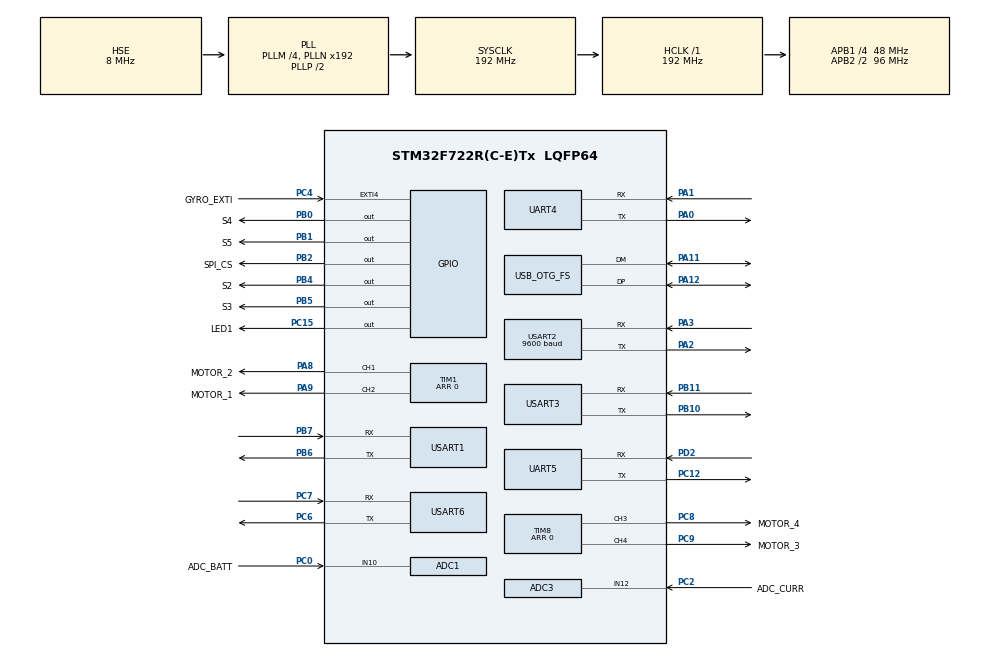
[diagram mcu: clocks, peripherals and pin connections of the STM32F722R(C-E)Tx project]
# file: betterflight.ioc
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ADC1.Channel-0\#ChannelRegularConversion=ADC_CHANNEL_10
ADC1.ClockPrescaler=ADC_CLOCK_SYNC_PCLK_DIV4
ADC1.NbrOfConversionFlag=1
ADC1.Rank-0\#ChannelRegularConversion=1
ADC1.SamplingTime-0\#ChannelRegularConversion=ADC_SAMPLETIME_3CYCLES
ADC1.master=1
ADC3.Channel-0\#ChannelRegularConversion=ADC_CHANNEL_12
ADC3.ClockPrescaler=ADC_CLOCK_SYNC_PCLK_DIV4
ADC3.NbrOfConversionFlag=1
ADC3.Rank-0\#ChannelRegularConversion=1
ADC3.SamplingTime-0\#ChannelRegularConversion=ADC_SAMPLETIME_3CYCLES
Dma.Request0=TIM1_CH1
Dma.Request1=TIM8_CH3
Dma.Request2=TIM8_CH4/TRIG/COM
Dma.Request3=TIM1_CH2
Dma.TIM1_CH1.0.Direction=DMA_MEMORY_TO_PERIPH
Dma.TIM1_CH1.0.FIFOMode=DMA_FIFOMODE_ENABLE
Dma.TIM1_CH1.0.FIFOThreshold=DMA_FIFO_THRESHOLD_1QUARTERFULL
Dma.TIM1_CH1.0.Instance=DMA2_Stream1
Dma.TIM1_CH1.0.MemBurst=DMA_MBURST_SINGLE
Dma.TIM1_CH1.0.MemDataAlignment=DMA_MDATAALIGN_WORD
Dma.TIM1_CH1.0.MemInc=DMA_MINC_ENABLE
Dma.TIM1_CH1.0.Mode=DMA_NORMAL
Dma.TIM1_CH1.0.PeriphBurst=DMA_PBURST_SINGLE
Dma.TIM1_CH1.0.PeriphDataAlignment=DMA_PDATAALIGN_WORD
Dma.TIM1_CH1.0.PeriphInc=DMA_PINC_DISABLE
Dma.TIM1_CH1.0.Priority=DMA_PRIORITY_HIGH
Dma.TIM1_CH2.3.Direction=DMA_MEMORY_TO_PERIPH
Dma.TIM1_CH2.3.FIFOMode=DMA_FIFOMODE_ENABLE
Dma.TIM1_CH2.3.FIFOThreshold=DMA_FIFO_THRESHOLD_FULL
Dma.TIM1_CH2.3.Instance=DMA2_Stream2
Dma.TIM1_CH2.3.MemBurst=DMA_MBURST_SINGLE
Dma.TIM1_CH2.3.MemDataAlignment=DMA_MDATAALIGN_WORD
Dma.TIM1_CH2.3.MemInc=DMA_MINC_ENABLE
Dma.TIM1_CH2.3.Mode=DMA_NORMAL
Dma.TIM1_CH2.3.PeriphBurst=DMA_PBURST_SINGLE
Dma.TIM1_CH2.3.PeriphDataAlignment=DMA_PDATAALIGN_WORD
Dma.TIM1_CH2.3.PeriphInc=DMA_PINC_DISABLE
Dma.TIM1_CH2.3.Priority=DMA_PRIORITY_HIGH
Dma.TIM8_CH3.1.Direction=DMA_MEMORY_TO_PERIPH
Dma.TIM8_CH3.1.FIFOMode=DMA_FIFOMODE_ENABLE
Dma.TIM8_CH3.1.FIFOThreshold=DMA_FIFO_THRESHOLD_1QUARTERFULL
Dma.TIM8_CH3.1.Instance=DMA2_Stream4
Dma.TIM8_CH3.1.MemBurst=DMA_MBURST_SINGLE
Dma.TIM8_CH3.1.MemDataAlignment=DMA_MDATAALIGN_WORD
Dma.TIM8_CH3.1.MemInc=DMA_MINC_ENABLE
Dma.TIM8_CH3.1.Mode=DMA_NORMAL
Dma.TIM8_CH3.1.PeriphBurst=DMA_PBURST_SINGLE
Dma.TIM8_CH3.1.PeriphDataAlignment=DMA_PDATAALIGN_WORD
Dma.TIM8_CH3.1.PeriphInc=DMA_PINC_DISABLE
Dma.TIM8_CH3.1.Priority=DMA_PRIORITY_HIGH
Dma.TIM8_CH4/TRIG/COM.2.Direction=DMA_MEMORY_TO_PERIPH
Dma.TIM8_CH4/TRIG/COM.2.FIFOMode=DMA_FIFOMODE_ENABLE
Dma.TIM8_CH4/TRIG/COM.2.FIFOThreshold=DMA_FIFO_THRESHOLD_1QUARTERFULL
Dma.TIM8_CH4/TRIG/COM.2.Instance=DMA2_Stream7
Dma.TIM8_CH4/TRIG/COM.2.MemBurst=DMA_MBURST_SINGLE
Dma.TIM8_CH4/TRIG/COM.2.MemDataAlignment=DMA_MDATAALIGN_WORD
Dma.TIM8_CH4/TRIG/COM.2.MemInc=DMA_MINC_ENABLE
Dma.TIM8_CH4/TRIG/COM.2.Mode=DMA_NORMAL
Dma.TIM8_CH4/TRIG/COM.2.PeriphBurst=DMA_PBURST_SINGLE
Dma.TIM8_CH4/TRIG/COM.2.PeriphDataAlignment=DMA_PDATAALIGN_WORD
Dma.TIM8_CH4/TRIG/COM.2.PeriphInc=DMA_PINC_DISABLE
Dma.TIM8_CH4/TRIG/COM.2.Priority=DMA_PRIORITY_HIGH
Mcu.Family=STM32F7
Mcu.Name=STM32F722R(C-E)Tx
Mcu.Package=LQFP64
NVIC.DMA2_Stream1_IRQn=true\:0\:0\:false\:false\:true\:false\:true\:true
NVIC.DMA2_Stream2_IRQn=true\:0\:0\:false\:false\:true\:false\:true\:true
NVIC.DMA2_Stream4_IRQn=true\:0\:0\:false\:false\:true\:false\:true\:true
NVIC.DMA2_Stream7_IRQn=true\:0\:0\:false\:false\:true\:false\:true\:true
NVIC.EXTI4_IRQn=true\:0\:0\:false\:false\:true\:true\:true\:true
NVIC.OTG_FS_IRQn=true\:0\:0\:false\:false\:true\:false\:true\:true
NVIC.PriorityGroup=NVIC_PRIORITYGROUP_4
NVIC.USART2_IRQn=true\:0\:0\:false\:false\:true\:true\:true\:true
PA0-WKUP.Mode=Asynchronous
PA0-WKUP.Signal=UART4_TX
PA1.Mode=Asynchronous
PA1.Signal=UART4_RX
PA11.Mode=Device_Only
PA11.Signal=USB_OTG_FS_DM
PA12.Mode=Device_Only
PA12.Signal=USB_OTG_FS_DP
PA13.Mode=Serial_Wire
PA13.Signal=SYS_JTMS-SWDIO
PA14.Mode=Serial_Wire
PA14.Signal=SYS_JTCK-SWCLK
PA15.GPIO_Label=LED_STRIP
PA15.Signal=S_TIM2_CH1_ETR
PA2.Mode=Asynchronous
PA2.Signal=USART2_TX
PA3.Mode=Asynchronous
PA3.Signal=USART2_RX
PA5.GPIO_Label=SPI_SCK
PA5.Signal=SPI1_SCK
PA6.GPIO_Label=SPI_MISO
PA6.Signal=SPI1_MISO
PA7.GPIO_Label=SPI_MOSI
PA7.Signal=SPI1_MOSI
PA8.GPIO_Label=MOTOR_2
PA8.Signal=S_TIM1_CH1
PA9.GPIO_Label=MOTOR_1
PA9.Signal=S_TIM1_CH2
PB0.GPIO_Label=S4
PB0.GPIO_PuPd=GPIO_PULLUP
PB0.GPIO_Speed=GPIO_SPEED_FREQ_VERY_HIGH
PB0.PinState=GPIO_PIN_SET
PB0.Signal=GPIO_Output
PB1.GPIO_Label=S5
PB1.GPIO_PuPd=GPIO_PULLUP
PB1.GPIO_Speed=GPIO_SPEED_FREQ_VERY_HIGH
PB1.PinState=GPIO_PIN_SET
PB1.Signal=GPIO_Output
PB10.Mode=Asynchronous
PB10.Signal=USART3_TX
PB11.Mode=Asynchronous
PB11.Signal=USART3_RX
PB14.GPIO_Label=S1
PB14.Signal=S_TIM12_CH1
PB2.GPIO_Label=SPI_CS
PB2.PinState=GPIO_PIN_SET
PB2.Signal=GPIO_Output
PB4.GPIO_Label=S2
PB4.GPIO_PuPd=GPIO_PULLUP
PB4.GPIO_Speed=GPIO_SPEED_FREQ_VERY_HIGH
PB4.PinState=GPIO_PIN_SET
PB4.Signal=GPIO_Output
PB5.GPIO_Label=S3
PB5.GPIO_PuPd=GPIO_PULLUP
PB5.GPIO_Speed=GPIO_SPEED_FREQ_VERY_HIGH
PB5.PinState=GPIO_PIN_SET
PB5.Signal=GPIO_Output
PB6.Mode=Asynchronous
PB6.Signal=USART1_TX
PB7.Mode=Asynchronous
PB7.Signal=USART1_RX
PB8.Signal=I2C1_SCL
PB9.Signal=I2C1_SDA
PC0.GPIO_Label=ADC_BATT
PC0.Signal=ADCx_IN10
PC12.Mode=Asynchronous
PC12.Signal=UART5_TX
PC15-OSC32_OUT.GPIO_Label=LED1
PC15-OSC32_OUT.Signal=GPIO_Output
PC2.GPIO_Label=ADC_CURR
PC2.Signal=ADCx_IN12
PC4.GPIO_Label=GYRO_EXTI
PC4.Signal=GPXTI4
PC6.Mode=Asynchronous
PC6.Signal=USART6_TX
PC7.Mode=Asynchronous
PC7.Signal=USART6_RX
PC8.GPIO_Label=MOTOR_4
PC8.Signal=S_TIM8_CH3
PC9.GPIO_Label=MOTOR_3
PC9.Signal=S_TIM8_CH4
PD2.Mode=Asynchronous
PD2.Signal=UART5_RX
PH0-OSC_IN.Mode=HSE-External-Oscillator
PH0-OSC_IN.Signal=RCC_OSC_IN
PH1-OSC_OUT.Mode=HSE-External-Oscillator
PH1-OSC_OUT.Signal=RCC_OSC_OUT
ProjectManager.HeapSize=0x300
ProjectManager.StackSize=0x400
ProjectManager.TargetToolchain=STM32CubeIDE
RCC.AHBFreq_Value=192000000
RCC.APB1CLKDivider=RCC_HCLK_DIV4
RCC.APB1Freq_Value=48000000
RCC.APB1TimFreq_Value=96000000
RCC.APB2CLKDivider=RCC_HCLK_DIV2
RCC.APB2Freq_Value=96000000
RCC.APB2TimFreq_Value=192000000
RCC.CortexFreq_Value=192000000
RCC.HCLKFreq_Value=192000000
RCC.HSE_VALUE=8000000
RCC.HSI_VALUE=16000000
RCC.LSE_VALUE=32768
RCC.PLL48CLockSelection=RCC_CLK48SOURCE_PLLSAIP
RCC.PLLM=4
RCC.PLLQ=5
RCC.PLLSAIN=96
RCC.PLLSAIP=RCC_PLLSAIP_DIV4
RCC.SYSCLKFreq_VALUE=192000000
RCC.SYSCLKSource=RCC_SYSCLKSOURCE_PLLCLK
RCC.USBFreq_Value=48000000
RCC.VCOOutputFreq_Value=384000000
SH.ADCx_IN10.0=ADC1_IN10,IN10
SH.ADCx_IN12.0=ADC3_IN12,IN12
SH.S_TIM12_CH1.0=TIM12_CH1
SH.S_TIM1_CH1.0=TIM1_CH1,PWM Generation1 CH1
SH.S_TIM1_CH2.0=TIM1_CH2,PWM Generation2 CH2
SH.S_TIM2_CH1_ETR.0=TIM2_CH1
SH.S_TIM8_CH3.0=TIM8_CH3,PWM Generation3 CH3
SH.S_TIM8_CH4.0=TIM8_CH4,PWM Generation4 CH4
TIM1.Channel-PWM\ Generation1\ CH1=TIM_CHANNEL_1
TIM1.Channel-PWM\ Generation2\ CH2=TIM_CHANNEL_2
TIM1.Period=0
TIM8.Channel-PWM\ Generation3\ CH3=TIM_CHANNEL_3
TIM8.Channel-PWM\ Generation4\ CH4=TIM_CHANNEL_4
TIM8.Period=0
USART1.VirtualMode-Asynchronous=VM_ASYNC
USART2.BaudRate=9600
USART2.VirtualMode-Asynchronous=VM_ASYNC
USART3.VirtualMode-Asynchronous=VM_ASYNC
USART6.VirtualMode=VM_ASYNC
USB_DEVICE.CLASS_NAME_FS=CDC
USB_DEVICE.VirtualMode-CDC_FS=Cdc
USB_DEVICE.VirtualModeFS=Cdc_FS
USB_OTG_FS.VirtualMode=Device_Only
VP_TIM1_VS_ClockSourceINT.Mode=Internal
VP_TIM8_VS_ClockSourceINT.Mode=Internal
VP_USB_DEVICE_VS_USB_DEVICE_CDC_FS.Mode=CDC_FS
board=custom

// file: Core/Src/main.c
/* USER CODE BEGIN Header */
/**
  ******************************************************************************
  * @file           : main.c
  * @brief          : Main program body
  ******************************************************************************
  * @attention
  *
  * Copyright (c) 2024 STMicroelectronics.
  * All rights reserved.
  *
  * This software is licensed under terms that can be found in the LICENSE file
  * in the root directory of this software component.
  * If no LICENSE file comes with this software, it is provided AS-IS.
  *
  ******************************************************************************
  */
/* USER CODE END Header */
#include "main.h"
#include "usb_device.h"

/* USER CODE BEGIN Includes */
#include <sys/errno.h>
#include <sys/unistd.h>
#include <stdio.h>
#include <string.h>

#include "mymain.h"
#include "log.h"
#include "misc.h"
#include "usb_device.h"
#include "usbd_cdc_if.h"
/* USER CODE END Includes */

ADC_HandleTypeDef hadc1;
ADC_HandleTypeDef hadc3;

TIM_HandleTypeDef htim1;
TIM_HandleTypeDef htim8;
DMA_HandleTypeDef hdma_tim1_ch1;
DMA_HandleTypeDef hdma_tim1_ch2;
DMA_HandleTypeDef hdma_tim8_ch3;
DMA_HandleTypeDef hdma_tim8_ch4_trig_com;

UART_HandleTypeDef huart4;
UART_HandleTypeDef huart5;
UART_HandleTypeDef huart1;
UART_HandleTypeDef huart2;
UART_HandleTypeDef huart3;
UART_HandleTypeDef huart6;

void SystemClock_Config(void);
static void MX_GPIO_Init(void);
static void MX_DMA_Init(void);
static void MX_UART4_Init(void);
static void MX_UART5_Init(void);
static void MX_USART1_UART_Init(void);
static void MX_USART2_UART_Init(void);
static void MX_USART3_UART_Init(void);
static void MX_USART6_UART_Init(void);
static void MX_ADC1_Init(void);
static void MX_ADC3_Init(void);
static void MX_TIM1_Init(void);
static void MX_TIM8_Init(void);

int main(void)
{

  /* MCU Configuration--------------------------------------------------------*/

  /* Reset of all peripherals, Initializes the Flash interface and the Systick. */
  HAL_Init();

  /* Configure the system clock */
  SystemClock_Config();

  /* Initialize all configured peripherals */
  MX_GPIO_Init();
  MX_DMA_Init();
  MX_UART4_Init();
  MX_UART5_Init();
  MX_USART1_UART_Init();
  MX_USART2_UART_Init();
  MX_USART3_UART_Init();
  MX_USART6_UART_Init();
  MX_USB_DEVICE_Init();
  MX_ADC1_Init();
  MX_ADC3_Init();
  MX_TIM1_Init();
  MX_TIM8_Init();
  /* USER CODE BEGIN 2 */

  myinit();
  mymain();
  /* USER CODE END 2 */

  /* Infinite loop */
  /* USER CODE BEGIN WHILE */

  while (1)
  {
      LOGW("In final loop, should not be here!");
      HAL_Delay(1000);
    /* USER CODE END WHILE */

  }
}

void SystemClock_Config(void)
{
  RCC_OscInitTypeDef RCC_OscInitStruct = {0};
  RCC_ClkInitTypeDef RCC_ClkInitStruct = {0};

  /** Configure the main internal regulator output voltage
  */
  __HAL_RCC_PWR_CLK_ENABLE();
  __HAL_PWR_VOLTAGESCALING_CONFIG(PWR_REGULATOR_VOLTAGE_SCALE1);

  /** Initializes the RCC Oscillators according to the specified parameters
  * in the RCC_OscInitTypeDef structure.
  */
  RCC_OscInitStruct.OscillatorType = RCC_OSCILLATORTYPE_HSE;
  RCC_OscInitStruct.HSEState = RCC_HSE_ON;
  RCC_OscInitStruct.PLL.PLLState = RCC_PLL_ON;
  RCC_OscInitStruct.PLL.PLLSource = RCC_PLLSOURCE_HSE;
  RCC_OscInitStruct.PLL.PLLM = 4;
  RCC_OscInitStruct.PLL.PLLN = 192;
  RCC_OscInitStruct.PLL.PLLP = RCC_PLLP_DIV2;
  RCC_OscInitStruct.PLL.PLLQ = 5;
  if (HAL_RCC_OscConfig(&RCC_OscInitStruct) != HAL_OK)
  {
    Error_Handler();
  }

  /** Activate the Over-Drive mode
  */
  if (HAL_PWREx_EnableOverDrive() != HAL_OK)
  {
    Error_Handler();
  }

  /** Initializes the CPU, AHB and APB buses clocks
  */
  RCC_ClkInitStruct.ClockType = RCC_CLOCKTYPE_HCLK|RCC_CLOCKTYPE_SYSCLK
                              |RCC_CLOCKTYPE_PCLK1|RCC_CLOCKTYPE_PCLK2;
  RCC_ClkInitStruct.SYSCLKSource = RCC_SYSCLKSOURCE_PLLCLK;
  RCC_ClkInitStruct.AHBCLKDivider = RCC_SYSCLK_DIV1;
  RCC_ClkInitStruct.APB1CLKDivider = RCC_HCLK_DIV4;
  RCC_ClkInitStruct.APB2CLKDivider = RCC_HCLK_DIV2;

  if (HAL_RCC_ClockConfig(&RCC_ClkInitStruct, FLASH_LATENCY_6) != HAL_OK)
  {
    Error_Handler();
  }
}

static void MX_ADC1_Init(void)
{

  ADC_ChannelConfTypeDef sConfig = {0};

  /** Configure the global features of the ADC (Clock, Resolution, Data Alignment and number of conversion)
  */
  hadc1.Instance = ADC1;
  hadc1.Init.ClockPrescaler = ADC_CLOCK_SYNC_PCLK_DIV4;
  hadc1.Init.Resolution = ADC_RESOLUTION_12B;
  hadc1.Init.ScanConvMode = ADC_SCAN_DISABLE;
  hadc1.Init.ContinuousConvMode = DISABLE;
  hadc1.Init.DiscontinuousConvMode = DISABLE;
  hadc1.Init.ExternalTrigConvEdge = ADC_EXTERNALTRIGCONVEDGE_NONE;
  hadc1.Init.ExternalTrigConv = ADC_SOFTWARE_START;
  hadc1.Init.DataAlign = ADC_DATAALIGN_RIGHT;
  hadc1.Init.NbrOfConversion = 1;
  hadc1.Init.DMAContinuousRequests = DISABLE;
  hadc1.Init.EOCSelection = ADC_EOC_SINGLE_CONV;
  if (HAL_ADC_Init(&hadc1) != HAL_OK)
  {
    Error_Handler();
  }

  /** Configure for the selected ADC regular channel its corresponding rank in the sequencer and its sample time.
  */
  sConfig.Channel = ADC_CHANNEL_10;
  sConfig.Rank = ADC_REGULAR_RANK_1;
  sConfig.SamplingTime = ADC_SAMPLETIME_3CYCLES;
  if (HAL_ADC_ConfigChannel(&hadc1, &sConfig) != HAL_OK)
  {
    Error_Handler();
  }

}

static void MX_ADC3_Init(void)
{

  ADC_ChannelConfTypeDef sConfig = {0};

  /** Configure the global features of the ADC (Clock, Resolution, Data Alignment and number of conversion)
  */
  hadc3.Instance = ADC3;
  hadc3.Init.ClockPrescaler = ADC_CLOCK_SYNC_PCLK_DIV4;
  hadc3.Init.Resolution = ADC_RESOLUTION_12B;
  hadc3.Init.ScanConvMode = ADC_SCAN_DISABLE;
  hadc3.Init.ContinuousConvMode = DISABLE;
  hadc3.Init.DiscontinuousConvMode = DISABLE;
  hadc3.Init.ExternalTrigConvEdge = ADC_EXTERNALTRIGCONVEDGE_NONE;
  hadc3.Init.ExternalTrigConv = ADC_SOFTWARE_START;
  hadc3.Init.DataAlign = ADC_DATAALIGN_RIGHT;
  hadc3.Init.NbrOfConversion = 1;
  hadc3.Init.DMAContinuousRequests = DISABLE;
  hadc3.Init.EOCSelection = ADC_EOC_SINGLE_CONV;
  if (HAL_ADC_Init(&hadc3) != HAL_OK)
  {
    Error_Handler();
  }

  /** Configure for the selected ADC regular channel its corresponding rank in the sequencer and its sample time.
  */
  sConfig.Channel = ADC_CHANNEL_12;
  sConfig.Rank = ADC_REGULAR_RANK_1;
  sConfig.SamplingTime = ADC_SAMPLETIME_3CYCLES;
  if (HAL_ADC_ConfigChannel(&hadc3, &sConfig) != HAL_OK)
  {
    Error_Handler();
  }

}

static void MX_TIM1_Init(void)
{

  TIM_ClockConfigTypeDef sClockSourceConfig = {0};
  TIM_MasterConfigTypeDef sMasterConfig = {0};
  TIM_OC_InitTypeDef sConfigOC = {0};
  TIM_BreakDeadTimeConfigTypeDef sBreakDeadTimeConfig = {0};

  htim1.Instance = TIM1;
  htim1.Init.Prescaler = 0;
  htim1.Init.CounterMode = TIM_COUNTERMODE_UP;
  htim1.Init.Period = 0;
  htim1.Init.ClockDivision = TIM_CLOCKDIVISION_DIV1;
  htim1.Init.RepetitionCounter = 0;
  htim1.Init.AutoReloadPreload = TIM_AUTORELOAD_PRELOAD_DISABLE;
  if (HAL_TIM_Base_Init(&htim1) != HAL_OK)
  {
    Error_Handler();
  }
  sClockSourceConfig.ClockSource = TIM_CLOCKSOURCE_INTERNAL;
  if (HAL_TIM_ConfigClockSource(&htim1, &sClockSourceConfig) != HAL_OK)
  {
    Error_Handler();
  }
  if (HAL_TIM_PWM_Init(&htim1) != HAL_OK)
  {
    Error_Handler();
  }
  sMasterConfig.MasterOutputTrigger = TIM_TRGO_RESET;
  sMasterConfig.MasterOutputTrigger2 = TIM_TRGO2_RESET;
  sMasterConfig.MasterSlaveMode = TIM_MASTERSLAVEMODE_DISABLE;
  if (HAL_TIMEx_MasterConfigSynchronization(&htim1, &sMasterConfig) != HAL_OK)
  {
    Error_Handler();
  }
  sConfigOC.OCMode = TIM_OCMODE_PWM1;
  sConfigOC.Pulse = 0;
  sConfigOC.OCPolarity = TIM_OCPOLARITY_HIGH;
  sConfigOC.OCNPolarity = TIM_OCNPOLARITY_HIGH;
  sConfigOC.OCFastMode = TIM_OCFAST_DISABLE;
  sConfigOC.OCIdleState = TIM_OCIDLESTATE_RESET;
  sConfigOC.OCNIdleState = TIM_OCNIDLESTATE_RESET;
  if (HAL_TIM_PWM_ConfigChannel(&htim1, &sConfigOC, TIM_CHANNEL_1) != HAL_OK)
  {
    Error_Handler();
  }
  if (HAL_TIM_PWM_ConfigChannel(&htim1, &sConfigOC, TIM_CHANNEL_2) != HAL_OK)
  {
    Error_Handler();
  }
  sBreakDeadTimeConfig.OffStateRunMode = TIM_OSSR_DISABLE;
  sBreakDeadTimeConfig.OffStateIDLEMode = TIM_OSSI_DISABLE;
  sBreakDeadTimeConfig.LockLevel = TIM_LOCKLEVEL_OFF;
  sBreakDeadTimeConfig.DeadTime = 0;
  sBreakDeadTimeConfig.BreakState = TIM_BREAK_DISABLE;
  sBreakDeadTimeConfig.BreakPolarity = TIM_BREAKPOLARITY_HIGH;
  sBreakDeadTimeConfig.BreakFilter = 0;
  sBreakDeadTimeConfig.Break2State = TIM_BREAK2_DISABLE;
  sBreakDeadTimeConfig.Break2Polarity = TIM_BREAK2POLARITY_HIGH;
  sBreakDeadTimeConfig.Break2Filter = 0;
  sBreakDeadTimeConfig.AutomaticOutput = TIM_AUTOMATICOUTPUT_DISABLE;
  if (HAL_TIMEx_ConfigBreakDeadTime(&htim1, &sBreakDeadTimeConfig) != HAL_OK)
  {
    Error_Handler();
  }
  HAL_TIM_MspPostInit(&htim1);

}

static void MX_TIM8_Init(void)
{

  TIM_ClockConfigTypeDef sClockSourceConfig = {0};
  TIM_MasterConfigTypeDef sMasterConfig = {0};
  TIM_OC_InitTypeDef sConfigOC = {0};
  TIM_BreakDeadTimeConfigTypeDef sBreakDeadTimeConfig = {0};

  htim8.Instance = TIM8;
  htim8.Init.Prescaler = 0;
  htim8.Init.CounterMode = TIM_COUNTERMODE_UP;
  htim8.Init.Period = 0;
  htim8.Init.ClockDivision = TIM_CLOCKDIVISION_DIV1;
  htim8.Init.RepetitionCounter = 0;
  htim8.Init.AutoReloadPreload = TIM_AUTORELOAD_PRELOAD_DISABLE;
  if (HAL_TIM_Base_Init(&htim8) != HAL_OK)
  {
    Error_Handler();
  }
  sClockSourceConfig.ClockSource = TIM_CLOCKSOURCE_INTERNAL;
  if (HAL_TIM_ConfigClockSource(&htim8, &sClockSourceConfig) != HAL_OK)
  {
    Error_Handler();
  }
  if (HAL_TIM_PWM_Init(&htim8) != HAL_OK)
  {
    Error_Handler();
  }
  sMasterConfig.MasterOutputTrigger = TIM_TRGO_RESET;
  sMasterConfig.MasterOutputTrigger2 = TIM_TRGO2_RESET;
  sMasterConfig.MasterSlaveMode = TIM_MASTERSLAVEMODE_DISABLE;
  if (HAL_TIMEx_MasterConfigSynchronization(&htim8, &sMasterConfig) != HAL_OK)
  {
    Error_Handler();
  }
  sConfigOC.OCMode = TIM_OCMODE_PWM1;
  sConfigOC.Pulse = 0;
  sConfigOC.OCPolarity = TIM_OCPOLARITY_HIGH;
  sConfigOC.OCNPolarity = TIM_OCNPOLARITY_HIGH;
  sConfigOC.OCFastMode = TIM_OCFAST_DISABLE;
  sConfigOC.OCIdleState = TIM_OCIDLESTATE_RESET;
  sConfigOC.OCNIdleState = TIM_OCNIDLESTATE_RESET;
  if (HAL_TIM_PWM_ConfigChannel(&htim8, &sConfigOC, TIM_CHANNEL_3) != HAL_OK)
  {
    Error_Handler();
  }
  if (HAL_TIM_PWM_ConfigChannel(&htim8, &sConfigOC, TIM_CHANNEL_4) != HAL_OK)
  {
    Error_Handler();
  }
  sBreakDeadTimeConfig.OffStateRunMode = TIM_OSSR_DISABLE;
  sBreakDeadTimeConfig.OffStateIDLEMode = TIM_OSSI_DISABLE;
  sBreakDeadTimeConfig.LockLevel = TIM_LOCKLEVEL_OFF;
  sBreakDeadTimeConfig.DeadTime = 0;
  sBreakDeadTimeConfig.BreakState = TIM_BREAK_DISABLE;
  sBreakDeadTimeConfig.BreakPolarity = TIM_BREAKPOLARITY_HIGH;
  sBreakDeadTimeConfig.BreakFilter = 0;
  sBreakDeadTimeConfig.Break2State = TIM_BREAK2_DISABLE;
  sBreakDeadTimeConfig.Break2Polarity = TIM_BREAK2POLARITY_HIGH;
  sBreakDeadTimeConfig.Break2Filter = 0;
  sBreakDeadTimeConfig.AutomaticOutput = TIM_AUTOMATICOUTPUT_DISABLE;
  if (HAL_TIMEx_ConfigBreakDeadTime(&htim8, &sBreakDeadTimeConfig) != HAL_OK)
  {
    Error_Handler();
  }
  HAL_TIM_MspPostInit(&htim8);

}

static void MX_UART4_Init(void)
{

  huart4.Instance = UART4;
  huart4.Init.BaudRate = 115200;
  huart4.Init.WordLength = UART_WORDLENGTH_8B;
  huart4.Init.StopBits = UART_STOPBITS_1;
  huart4.Init.Parity = UART_PARITY_NONE;
  huart4.Init.Mode = UART_MODE_TX_RX;
  huart4.Init.HwFlowCtl = UART_HWCONTROL_NONE;
  huart4.Init.OverSampling = UART_OVERSAMPLING_16;
  huart4.Init.OneBitSampling = UART_ONE_BIT_SAMPLE_DISABLE;
  huart4.AdvancedInit.AdvFeatureInit = UART_ADVFEATURE_NO_INIT;
  if (HAL_UART_Init(&huart4) != HAL_OK)
  {
    Error_Handler();
  }

}

static void MX_UART5_Init(void)
{

  huart5.Instance = UART5;
  huart5.Init.BaudRate = 115200;
  huart5.Init.WordLength = UART_WORDLENGTH_8B;
  huart5.Init.StopBits = UART_STOPBITS_1;
  huart5.Init.Parity = UART_PARITY_NONE;
  huart5.Init.Mode = UART_MODE_TX_RX;
  huart5.Init.HwFlowCtl = UART_HWCONTROL_NONE;
  huart5.Init.OverSampling = UART_OVERSAMPLING_16;
  huart5.Init.OneBitSampling = UART_ONE_BIT_SAMPLE_DISABLE;
  huart5.AdvancedInit.AdvFeatureInit = UART_ADVFEATURE_NO_INIT;
  if (HAL_UART_Init(&huart5) != HAL_OK)
  {
    Error_Handler();
  }

}

static void MX_USART1_UART_Init(void)
{

  huart1.Instance = USART1;
  huart1.Init.BaudRate = 115200;
  huart1.Init.WordLength = UART_WORDLENGTH_8B;
  huart1.Init.StopBits = UART_STOPBITS_1;
  huart1.Init.Parity = UART_PARITY_NONE;
  huart1.Init.Mode = UART_MODE_TX_RX;
  huart1.Init.HwFlowCtl = UART_HWCONTROL_NONE;
  huart1.Init.OverSampling = UART_OVERSAMPLING_16;
  huart1.Init.OneBitSampling = UART_ONE_BIT_SAMPLE_DISABLE;
  huart1.AdvancedInit.AdvFeatureInit = UART_ADVFEATURE_NO_INIT;
  if (HAL_UART_Init(&huart1) != HAL_OK)
  {
    Error_Handler();
  }

}

static void MX_USART2_UART_Init(void)
{

  huart2.Instance = USART2;
  huart2.Init.BaudRate = 9600;
  huart2.Init.WordLength = UART_WORDLENGTH_8B;
  huart2.Init.StopBits = UART_STOPBITS_1;
  huart2.Init.Parity = UART_PARITY_NONE;
  huart2.Init.Mode = UART_MODE_TX_RX;
  huart2.Init.HwFlowCtl = UART_HWCONTROL_NONE;
  huart2.Init.OverSampling = UART_OVERSAMPLING_16;
  huart2.Init.OneBitSampling = UART_ONE_BIT_SAMPLE_DISABLE;
  huart2.AdvancedInit.AdvFeatureInit = UART_ADVFEATURE_NO_INIT;
  if (HAL_UART_Init(&huart2) != HAL_OK)
  {
    Error_Handler();
  }

}

static void MX_USART3_UART_Init(void)
{

  huart3.Instance = USART3;
  huart3.Init.BaudRate = 115200;
  huart3.Init.WordLength = UART_WORDLENGTH_8B;
  huart3.Init.StopBits = UART_STOPBITS_1;
  huart3.Init.Parity = UART_PARITY_NONE;
  huart3.Init.Mode = UART_MODE_TX_RX;
  huart3.Init.HwFlowCtl = UART_HWCONTROL_NONE;
  huart3.Init.OverSampling = UART_OVERSAMPLING_16;
  huart3.Init.OneBitSampling = UART_ONE_BIT_SAMPLE_DISABLE;
  huart3.AdvancedInit.AdvFeatureInit = UART_ADVFEATURE_NO_INIT;
  if (HAL_UART_Init(&huart3) != HAL_OK)
  {
    Error_Handler();
  }

}

static void MX_USART6_UART_Init(void)
{

  huart6.Instance = USART6;
  huart6.Init.BaudRate = 115200;
  huart6.Init.WordLength = UART_WORDLENGTH_8B;
  huart6.Init.StopBits = UART_STOPBITS_1;
  huart6.Init.Parity = UART_PARITY_NONE;
  huart6.Init.Mode = UART_MODE_TX_RX;
  huart6.Init.HwFlowCtl = UART_HWCONTROL_NONE;
  huart6.Init.OverSampling = UART_OVERSAMPLING_16;
  huart6.Init.OneBitSampling = UART_ONE_BIT_SAMPLE_DISABLE;
  huart6.AdvancedInit.AdvFeatureInit = UART_ADVFEATURE_NO_INIT;
  if (HAL_UART_Init(&huart6) != HAL_OK)
  {
    Error_Handler();
  }

}

static void MX_DMA_Init(void)
{

  /* DMA controller clock enable */
  __HAL_RCC_DMA2_CLK_ENABLE();

  /* DMA interrupt init */
  /* DMA2_Stream1_IRQn interrupt configuration */
  HAL_NVIC_SetPriority(DMA2_Stream1_IRQn, 0, 0);
  HAL_NVIC_EnableIRQ(DMA2_Stream1_IRQn);
  /* DMA2_Stream2_IRQn interrupt configuration */
  HAL_NVIC_SetPriority(DMA2_Stream2_IRQn, 0, 0);
  HAL_NVIC_EnableIRQ(DMA2_Stream2_IRQn);
  /* DMA2_Stream4_IRQn interrupt configuration */
  HAL_NVIC_SetPriority(DMA2_Stream4_IRQn, 0, 0);
  HAL_NVIC_EnableIRQ(DMA2_Stream4_IRQn);
  /* DMA2_Stream7_IRQn interrupt configuration */
  HAL_NVIC_SetPriority(DMA2_Stream7_IRQn, 0, 0);
  HAL_NVIC_EnableIRQ(DMA2_Stream7_IRQn);

}

static void MX_GPIO_Init(void)
{
  GPIO_InitTypeDef GPIO_InitStruct = {0};

  /* GPIO Ports Clock Enable */
  __HAL_RCC_GPIOC_CLK_ENABLE();
  __HAL_RCC_GPIOH_CLK_ENABLE();
  __HAL_RCC_GPIOA_CLK_ENABLE();
  __HAL_RCC_GPIOB_CLK_ENABLE();
  __HAL_RCC_GPIOD_CLK_ENABLE();

  /*Configure GPIO pin Output Level */
  HAL_GPIO_WritePin(LED1_GPIO_Port, LED1_Pin, GPIO_PIN_RESET);

  /*Configure GPIO pin Output Level */
  HAL_GPIO_WritePin(GPIOB, S4_Pin|S5_Pin|SPI_CS_Pin|S2_Pin
                          |S3_Pin, GPIO_PIN_SET);

  /*Configure GPIO pin : LED1_Pin */
  GPIO_InitStruct.Pin = LED1_Pin;
  GPIO_InitStruct.Mode = GPIO_MODE_OUTPUT_PP;
  GPIO_InitStruct.Pull = GPIO_NOPULL;
  GPIO_InitStruct.Speed = GPIO_SPEED_FREQ_LOW;
  HAL_GPIO_Init(LED1_GPIO_Port, &GPIO_InitStruct);

  /*Configure GPIO pins : SPI_SCK_Pin SPI_MISO_Pin SPI_MOSI_Pin */
  GPIO_InitStruct.Pin = SPI_SCK_Pin|SPI_MISO_Pin|SPI_MOSI_Pin;
  GPIO_InitStruct.Mode = GPIO_MODE_AF_PP;
  GPIO_InitStruct.Pull = GPIO_NOPULL;
  GPIO_InitStruct.Speed = GPIO_SPEED_FREQ_VERY_HIGH;
  GPIO_InitStruct.Alternate = GPIO_AF5_SPI1;
  HAL_GPIO_Init(GPIOA, &GPIO_InitStruct);

  /*Configure GPIO pin : GYRO_EXTI_Pin */
  GPIO_InitStruct.Pin = GYRO_EXTI_Pin;
  GPIO_InitStruct.Mode = GPIO_MODE_IT_RISING;
  GPIO_InitStruct.Pull = GPIO_NOPULL;
  HAL_GPIO_Init(GYRO_EXTI_GPIO_Port, &GPIO_InitStruct);

  /*Configure GPIO pins : S4_Pin S5_Pin S2_Pin S3_Pin */
  GPIO_InitStruct.Pin = S4_Pin|S5_Pin|S2_Pin|S3_Pin;
  GPIO_InitStruct.Mode = GPIO_MODE_OUTPUT_PP;
  GPIO_InitStruct.Pull = GPIO_PULLUP;
  GPIO_InitStruct.Speed = GPIO_SPEED_FREQ_VERY_HIGH;
  HAL_GPIO_Init(GPIOB, &GPIO_InitStruct);

  /*Configure GPIO pin : SPI_CS_Pin */
  GPIO_InitStruct.Pin = SPI_CS_Pin;
  GPIO_InitStruct.Mode = GPIO_MODE_OUTPUT_PP;
  GPIO_InitStruct.Pull = GPIO_NOPULL;
  GPIO_InitStruct.Speed = GPIO_SPEED_FREQ_LOW;
  HAL_GPIO_Init(SPI_CS_GPIO_Port, &GPIO_InitStruct);

  /*Configure GPIO pin : S1_Pin */
  GPIO_InitStruct.Pin = S1_Pin;
  GPIO_InitStruct.Mode = GPIO_MODE_AF_PP;
  GPIO_InitStruct.Pull = GPIO_NOPULL;
  GPIO_InitStruct.Speed = GPIO_SPEED_FREQ_LOW;
  GPIO_InitStruct.Alternate = GPIO_AF9_TIM12;
  HAL_GPIO_Init(S1_GPIO_Port, &GPIO_InitStruct);

  /*Configure GPIO pin : LED_STRIP_Pin */
  GPIO_InitStruct.Pin = LED_STRIP_Pin;
  GPIO_InitStruct.Mode = GPIO_MODE_AF_PP;
  GPIO_InitStruct.Pull = GPIO_NOPULL;
  GPIO_InitStruct.Speed = GPIO_SPEED_FREQ_LOW;
  GPIO_InitStruct.Alternate = GPIO_AF1_TIM2;
  HAL_GPIO_Init(LED_STRIP_GPIO_Port, &GPIO_InitStruct);

  /*Configure GPIO pins : PB8 PB9 */
  GPIO_InitStruct.Pin = GPIO_PIN_8|GPIO_PIN_9;
  GPIO_InitStruct.Mode = GPIO_MODE_AF_OD;
  GPIO_InitStruct.Pull = GPIO_NOPULL;
  GPIO_InitStruct.Speed = GPIO_SPEED_FREQ_VERY_HIGH;
  GPIO_InitStruct.Alternate = GPIO_AF4_I2C1;
  HAL_GPIO_Init(GPIOB, &GPIO_InitStruct);

  /* EXTI interrupt init*/
  HAL_NVIC_SetPriority(EXTI4_IRQn, 0, 0);
  HAL_NVIC_EnableIRQ(EXTI4_IRQn);

}

void Error_Handler(void)
{
  __disable_irq();
  while (1)
  {
  }
}
